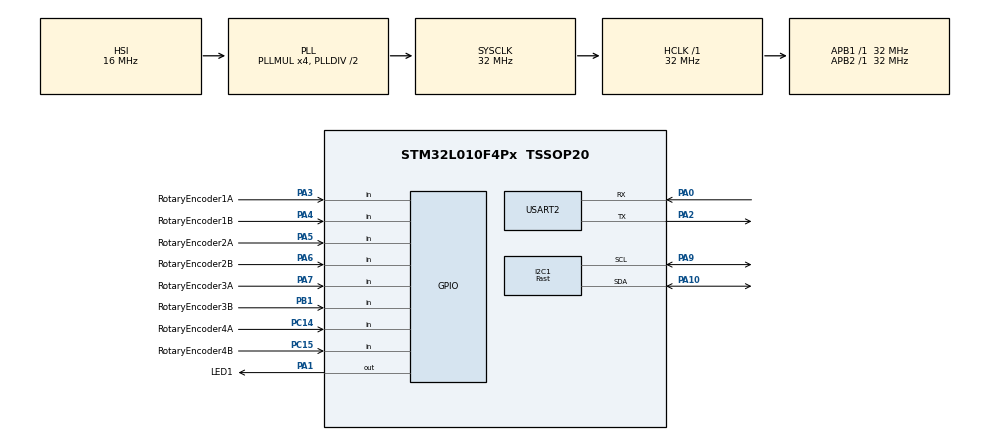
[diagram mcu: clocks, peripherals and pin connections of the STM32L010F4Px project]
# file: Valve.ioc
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Dma.Request0=USART2_RX
Dma.USART2_RX.0.Direction=DMA_PERIPH_TO_MEMORY
Dma.USART2_RX.0.Instance=DMA1_Channel3
Dma.USART2_RX.0.MemDataAlignment=DMA_MDATAALIGN_BYTE
Dma.USART2_RX.0.MemInc=DMA_MINC_ENABLE
Dma.USART2_RX.0.Mode=DMA_CIRCULAR
Dma.USART2_RX.0.PeriphDataAlignment=DMA_PDATAALIGN_BYTE
Dma.USART2_RX.0.PeriphInc=DMA_PINC_DISABLE
Dma.USART2_RX.0.Priority=DMA_PRIORITY_LOW
I2C1.I2C_Speed_Mode=I2C_Fast
I2C1.OwnAddress=0x40
I2C1.Timing=0x00300F38
Mcu.Family=STM32L0
Mcu.Name=STM32L010F4Px
Mcu.Package=TSSOP20
NVIC.DMA1_Channel2_3_IRQn=true\:0\:0\:false\:false\:true\:false\:true
NVIC.I2C1_IRQn=true\:0\:0\:false\:false\:true\:true\:true
PA0-CK_IN.Mode=Asynchronous
PA0-CK_IN.Signal=USART2_RX
PA1.GPIO_Label=LED1
PA1.Signal=GPIO_Output
PA10.Mode=I2C
PA10.Signal=I2C1_SDA
PA13.Mode=Serial_Wire
PA13.Signal=SYS_SWDIO
PA14.Mode=Serial_Wire
PA14.Signal=SYS_SWCLK
PA2.Mode=Asynchronous
PA2.Signal=USART2_TX
PA3.GPIO_Label=RotaryEncoder1A
PA3.GPIO_PuPd=GPIO_PULLUP
PA3.Signal=GPIO_Input
PA4.GPIO_Label=RotaryEncoder1B
PA4.GPIO_PuPd=GPIO_PULLUP
PA4.Signal=GPIO_Input
PA5.GPIO_Label=RotaryEncoder2A
PA5.GPIO_PuPd=GPIO_PULLUP
PA5.Signal=GPIO_Input
PA6.GPIO_Label=RotaryEncoder2B
PA6.GPIO_PuPd=GPIO_PULLUP
PA6.Signal=GPIO_Input
PA7.GPIO_Label=RotaryEncoder3A
PA7.GPIO_PuPd=GPIO_PULLUP
PA7.Signal=GPIO_Input
PA9.Mode=I2C
PA9.Signal=I2C1_SCL
PB1.GPIO_Label=RotaryEncoder3B
PB1.GPIO_PuPd=GPIO_PULLUP
PB1.Signal=GPIO_Input
PC14-OSC32_IN.GPIO_Label=RotaryEncoder4A
PC14-OSC32_IN.GPIO_PuPd=GPIO_PULLUP
PC14-OSC32_IN.Signal=GPIO_Input
PC15-OSC32_OUT.GPIO_Label=RotaryEncoder4B
PC15-OSC32_OUT.GPIO_PuPd=GPIO_PULLUP
PC15-OSC32_OUT.Signal=GPIO_Input
ProjectManager.HeapSize=0x200
ProjectManager.StackSize=0x200
ProjectManager.TargetToolchain=MDK-ARM V5.27
RCC.AHBFreq_Value=32000000
RCC.APB1Freq_Value=32000000
RCC.APB1TimFreq_Value=32000000
RCC.APB2Freq_Value=32000000
RCC.APB2TimFreq_Value=32000000
RCC.HCLKFreq_Value=32000000
RCC.HSE_VALUE=8000000
RCC.HSI16_VALUE=16000000
RCC.HSI_VALUE=16000000
RCC.LSE_VALUE=32768
RCC.MSI_VALUE=2097000
RCC.PLLMUL=RCC_PLLMUL_4
RCC.SYSCLKFreq_VALUE=32000000
RCC.SYSCLKSource=RCC_SYSCLKSOURCE_PLLCLK
RCC.VCOOutputFreq_Value=64000000
USART2.VirtualMode=VM_ASYNC
board=custom

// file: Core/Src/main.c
/* USER CODE BEGIN Header */
/**
  ******************************************************************************
  * @file           : main.c
  * @brief          : Main program body
  ******************************************************************************
  * @attention
  *
  * <h2><center>&copy; Copyright (c) 2021 STMicroelectronics.
  * All rights reserved.</center></h2>
  *
  * This software component is licensed by ST under BSD 3-Clause license,
  * the "License"; You may not use this file except in compliance with the
  * License. You may obtain a copy of the License at:
  *                        opensource.org/licenses/BSD-3-Clause
  *
  ******************************************************************************
  */
/* USER CODE END Header */
#include "main.h"
#include "dma.h"
#include "i2c.h"
#include "usart.h"
#include "gpio.h"

/* USER CODE BEGIN Includes */
#include "stm32l0xx_hal_gpio.h"
#include "ValveMain.h"
/* USER CODE END Includes */

void SystemClock_Config(void);

int main(void)
{

  /* MCU Configuration--------------------------------------------------------*/

  /* Reset of all peripherals, Initializes the Flash interface and the Systick. */
  HAL_Init();

  /* Configure the system clock */
  SystemClock_Config();

  /* Initialize all configured peripherals */
  MX_GPIO_Init();
  MX_DMA_Init();
  MX_USART2_UART_Init();
  MX_I2C1_Init();
  /* USER CODE BEGIN 2 */
  ValveMain();
  /* USER CODE END 2 */

  /* Infinite loop */
  /* USER CODE BEGIN WHILE */
  while (1)
  {
    HAL_GPIO_WritePin(LED1_GPIO_Port, LED1_Pin, GPIO_PIN_SET);
    HAL_Delay(500);
    HAL_GPIO_WritePin(LED1_GPIO_Port, LED1_Pin, GPIO_PIN_RESET);
    HAL_Delay(500);
    /* USER CODE END WHILE */

  }
}

void SystemClock_Config(void)
{
  RCC_OscInitTypeDef RCC_OscInitStruct = {0};
  RCC_ClkInitTypeDef RCC_ClkInitStruct = {0};
  RCC_PeriphCLKInitTypeDef PeriphClkInit = {0};

  /** Configure the main internal regulator output voltage
  */
  __HAL_PWR_VOLTAGESCALING_CONFIG(PWR_REGULATOR_VOLTAGE_SCALE1);
  /** Initializes the RCC Oscillators according to the specified parameters
  * in the RCC_OscInitTypeDef structure.
  */
  RCC_OscInitStruct.OscillatorType = RCC_OSCILLATORTYPE_HSI;
  RCC_OscInitStruct.HSIState = RCC_HSI_ON;
  RCC_OscInitStruct.HSICalibrationValue = RCC_HSICALIBRATION_DEFAULT;
  RCC_OscInitStruct.PLL.PLLState = RCC_PLL_ON;
  RCC_OscInitStruct.PLL.PLLSource = RCC_PLLSOURCE_HSI;
  RCC_OscInitStruct.PLL.PLLMUL = RCC_PLLMUL_4;
  RCC_OscInitStruct.PLL.PLLDIV = RCC_PLLDIV_2;
  if (HAL_RCC_OscConfig(&RCC_OscInitStruct) != HAL_OK)
  {
    Error_Handler();
  }
  /** Initializes the CPU, AHB and APB buses clocks
  */
  RCC_ClkInitStruct.ClockType = RCC_CLOCKTYPE_HCLK|RCC_CLOCKTYPE_SYSCLK
                              |RCC_CLOCKTYPE_PCLK1|RCC_CLOCKTYPE_PCLK2;
  RCC_ClkInitStruct.SYSCLKSource = RCC_SYSCLKSOURCE_PLLCLK;
  RCC_ClkInitStruct.AHBCLKDivider = RCC_SYSCLK_DIV1;
  RCC_ClkInitStruct.APB1CLKDivider = RCC_HCLK_DIV1;
  RCC_ClkInitStruct.APB2CLKDivider = RCC_HCLK_DIV1;

  if (HAL_RCC_ClockConfig(&RCC_ClkInitStruct, FLASH_LATENCY_1) != HAL_OK)
  {
    Error_Handler();
  }
  PeriphClkInit.PeriphClockSelection = RCC_PERIPHCLK_USART2|RCC_PERIPHCLK_I2C1;
  PeriphClkInit.Usart2ClockSelection = RCC_USART2CLKSOURCE_PCLK1;
  PeriphClkInit.I2c1ClockSelection = RCC_I2C1CLKSOURCE_PCLK1;
  if (HAL_RCCEx_PeriphCLKConfig(&PeriphClkInit) != HAL_OK)
  {
    Error_Handler();
  }
}

void Error_Handler(void)
{
  __disable_irq();
  while (1)
  {
  }
}

/************************ (C) COPYRIGHT STMicroelectronics *****END OF FILE****/
